# ipro7 register map
Vendor: intelpro; Series: BTBLE
CPU: ipro7, little endian
Registers are 32-bit, read-write, reset 0x0 unless marked. A register's access mark holds for its fields unless they carry their own. Offsets are from the block's base; [hi:lo] are bit positions.

## AON
Base 0x3008F000
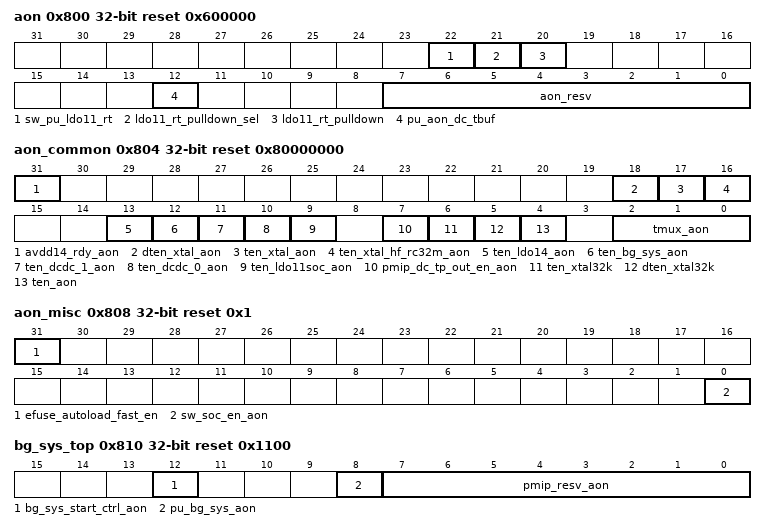
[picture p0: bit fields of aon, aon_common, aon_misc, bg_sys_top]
0x800 aon reset 0x600000
  [22] sw_pu_ldo11_rt
  [21] ldo11_rt_pulldown_sel — 0: hardware control pulldown when pu_ldo11rt=0, 1: register control
  [20] ldo11_rt_pulldown — 1: pulldown
  [12] pu_aon_dc_tbuf
  [7:0] aon_resv
0x804 aon_common reset 0x80000000 (reset mask 0x7FFFFFFF)
  [31] avdd14_rdy_aon ro — avdd14 power ready
  [18] dten_xtal_aon
  [17] ten_xtal_aon
  [16] ten_xtal_hf_rc32m_aon
  [13] ten_ldo14_aon — ldo14 dc test en
  [12] ten_bg_sys_aon — bgsys dc test en
  [11] ten_dcdc_1_aon — dcdc14 dc test1 en
  [10] ten_dcdc_0_aon — dcdc14 dc test0 en
  [9] ten_ldo11soc_aon
  [7] pmip_dc_tp_out_en_aon — dc test switch enable
  [6] ten_xtal32k — 32K crystal voltage test enable
  [5] dten_xtal32k — 32K crystal output clock test enable
  [4] ten_aon
  [2:0] tmux_aon
0x808 aon_misc reset 0x1
  [31] efuse_autoload_fast_en — 0:efuse autoload all 1k bits (49us) 1:efuse autoload first hw config words 0x0~0x8 only (9us) and release reset early
  [0] sw_soc_en_aon
0x810 bg_sys_top reset 0x1100
  [12] bg_sys_start_ctrl_aon — 0: supply voltage<2.3V, 1:supply voltage>=2.3V
  [8] pu_bg_sys_aon — power up system bandgap
  [7:0] pmip_resv_aon
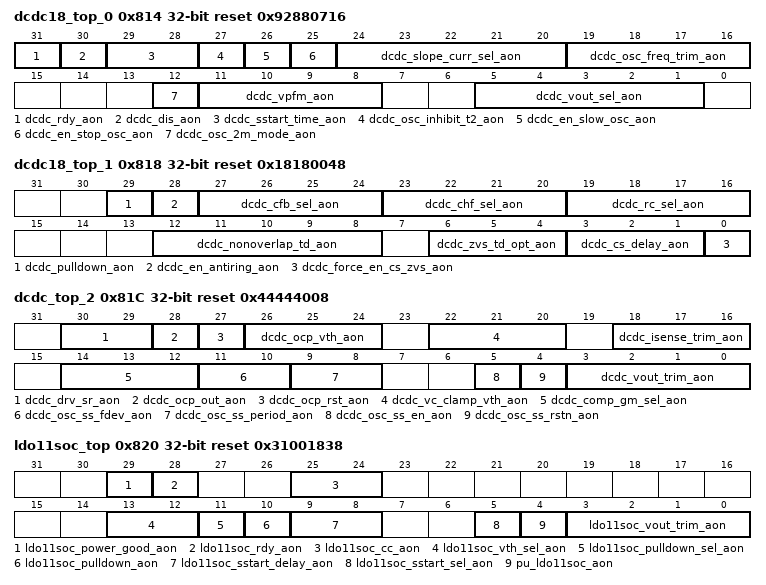
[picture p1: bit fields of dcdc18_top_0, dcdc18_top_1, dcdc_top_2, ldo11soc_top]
0x814 dcdc18_top_0 reset 0x92880716 (reset mask 0x7FFFFFFF)
  [31] dcdc_rdy_aon ro
  [30] dcdc_dis_aon — 1: disable dcdc function, for DCDC bypass mode
  [29:28] dcdc_sstart_time_aon — soft start time option
  [27] dcdc_osc_inhibit_t2_aon — inhibit t2 of osc
  [26] dcdc_en_slow_osc_aon — slow osc
  [25] dcdc_en_stop_osc_aon — stop osc
  [24:20] dcdc_slope_curr_sel_aon — current selection for slope compensation 8: if inductor value=2.2uH 14: if inductor value=1uH 4: if inductor value=4.7uH
  [19:16] dcdc_osc_freq_trim_aon — osc frequency trimming bits
  [12] dcdc_osc_2m_mode_aon — osc frequency selection, default 1MHz
  [11:8] dcdc_vpfm_aon — pfm mode threshold
  [5:1] dcdc_vout_sel_aon — output voltage selection, default 1.4V
0x818 dcdc18_top_1 reset 0x18180048
  [29] dcdc_pulldown_aon — output pulldown option 0: floating output when disable 1: pulldown output to ground when disable
  [28] dcdc_en_antiring_aon — antiring enable
  [27:24] dcdc_cfb_sel_aon — compensation cfb selection
  [23:20] dcdc_chf_sel_aon — compensation chf selection
  [19:16] dcdc_rc_sel_aon — compensation rc selection
  [12:8] dcdc_nonoverlap_td_aon — nonoverlap clock delay option
  [6:4] dcdc_zvs_td_opt_aon — zvs circuits enable delay option
  [3:1] dcdc_cs_delay_aon — cs circuits enable delay option
  [0] dcdc_force_en_cs_zvs_aon — force cs and zvs circuits enablable
0x81C dcdc_top_2 reset 0x44444008 (reset mask 0xEFFFFFFF)
  [30:29] dcdc_drv_sr_aon — powerMOS driver slew rate selection: 0: SR *1, 1: SR *2, 2: SR *4, 3: SR *40
  [28] dcdc_ocp_out_aon ro — ocp latched output
  [27] dcdc_ocp_rst_aon — reset dcdc_ocp_out_aon latch
  [26:24] dcdc_ocp_vth_aon — ocp threshold voltage
  [22:20] dcdc_vc_clamp_vth_aon — vc clamp threshold voltage
  [18:16] dcdc_isense_trim_aon — current sense R tuning
  [14:12] dcdc_comp_gm_sel_aon — compensator OTA gm tuning
  [11:10] dcdc_osc_ss_fdev_aon — osc spread spectrum frequency deviation
  [9:8] dcdc_osc_ss_period_aon — osc spread spectrum period
  [5] dcdc_osc_ss_en_aon — osc spread spectrum enable
  [4] dcdc_osc_ss_rstn_aon
  [3:0] dcdc_vout_trim_aon — output voltage trim 0: 93%, 1: 94%, 7: 100%, 8: 101%, 15: 108%
0x820 ldo11soc_top reset 0x31001838 (reset mask 0xCFFFFFFF)
  [29] ldo11soc_power_good_aon ro
  [28] ldo11soc_rdy_aon ro
  [25:24] ldo11soc_cc_aon — ldo11soc compensation capacitor option
  [13:12] ldo11soc_vth_sel_aon — vdd11soc pwr_ok detection threshold selection
  [11] ldo11soc_pulldown_sel_aon — ldo11 output pulldown signal selection 0: vout pulldown controlled by pd signal 1: vout pulldown controlled by pulldown signal
  [10] ldo11soc_pulldown_aon — vout pulldown signal 0: floating output 1: pulldown output to ground
  [9:8] ldo11soc_sstart_delay_aon — soft start delay time option
  [5] ldo11soc_sstart_sel_aon — ldo11 soft start select option 0: no soft start 1: with soft start function
  [4] pu_ldo11soc_aon — power up ldo11soc
  [3:0] ldo11soc_vout_trim_aon — output voltage trim: 0: 92%, .. 8: 100%, .. 15: 107%; 1%/step
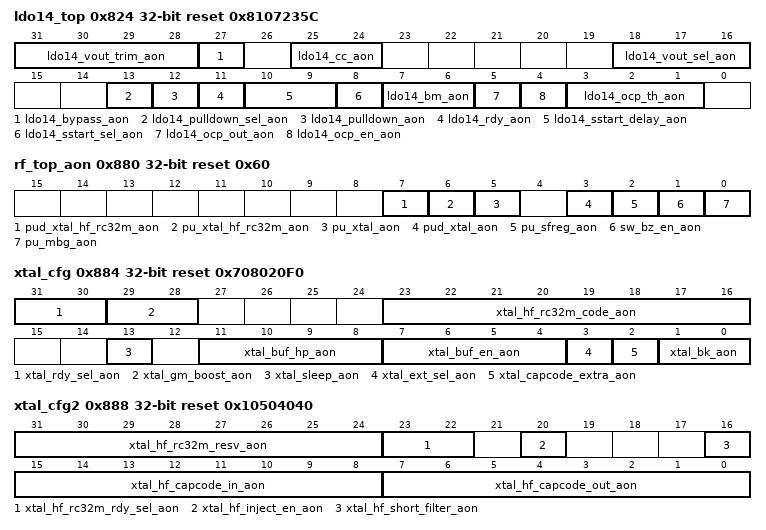
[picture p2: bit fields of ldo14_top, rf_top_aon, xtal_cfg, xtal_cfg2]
0x824 ldo14_top reset 0x8107235C (reset mask 0xFFFFF7DF)
  [31:28] ldo14_vout_trim_aon — output voltage trim 0: 92%, .. 8: 100%, .. 15: 107%; 1%/step
  [27] ldo14_bypass_aon — bypass enable. 702L_topldo14 donot have this function
  [25:24] ldo14_cc_aon — compensation capacitor option
  [18:16] ldo14_vout_sel_aon — output voltage selection, 0: 1.30, 1: 1.35, 2: 1.40, 3: 1.45, 4: 1.50, 5: 1.60, 6:1.70, 7: 1.80
  [13] ldo14_pulldown_sel_aon — output pulldown signal selection 0: vout pulldown controlled by pd signal 1: vout pulldown controlled by pulldown signal
  [12] ldo14_pulldown_aon — vout pulldown signal 0: floating output 1: pulldown output to ground
  [11] ldo14_rdy_aon ro — ldo14 ready signal
  [10:9] ldo14_sstart_delay_aon — soft-start delay time selection, 0: 50us, 1: 100us, 2: 150us, 3: 200us
  [8] ldo14_sstart_sel_aon — ldo14 soft start select option 0: no soft start 1: with soft start function
  [7:6] ldo14_bm_aon — bias mode selection
  [5] ldo14_ocp_out_aon ro — ldo14 ocp flag
  [4] ldo14_ocp_en_aon — ldo14 ocp enable
  [3:1] ldo14_ocp_th_aon — ocp threshold current selection; 0: 100mA, 1: 100mA, 2: 120mA, 3: 150mA, 4: 200mA, 5: 250mA, 6: 300mA, 7: 350mA
0x828 psw_irrcv
  [0] pu_ir_psw_aon — power up ir rx switch
0x82C rc32m_ctrl0_aon reset 0x60
  [7:0] rc32m_code_fr_ext — External code In for frequency setting
0x880 rf_top_aon reset 0x60 (reset mask 0xFFFFFF77)
  [7] pud_xtal_hf_rc32m_aon ro
  [6] pu_xtal_hf_rc32m_aon
  [5] pu_xtal_aon — power up xtal
  [3] pud_xtal_aon ro
  [2] pu_sfreg_aon
  [1] sw_bz_en_aon
  [0] pu_mbg_aon
0x884 xtal_cfg reset 0x708020F0
  [31:30] xtal_rdy_sel_aon — 0:128us, 1:256us, 2:512us, 3:1ms
  [29:28] xtal_gm_boost_aon — 1: larger negative gm in xtal
  [23:16] xtal_hf_rc32m_code_aon
  [13] xtal_sleep_aon — set 32M xtal in sleep mode
  [11:8] xtal_buf_hp_aon — set xtal buffer to high performance mode
  [7:4] xtal_buf_en_aon — enable xtal output buffer
  [3] xtal_ext_sel_aon — use offchip clock
  [2] xtal_capcode_extra_aon — Extra capacitor for supporting 15pF loading (also copy from efuse)
  [1:0] xtal_bk_aon — reseved for xtal
0x888 xtal_cfg2 reset 0x10504040
  [31:24] xtal_hf_rc32m_resv_aon — [3]: dten_xtal_rc32m_aon； [2]: dten_xtal_rc32m_rdy_aon； [5:4]: xtal_hf_ldo11_vsel；default 01 [6]: xtal_hf_injection_signal_sel; default 0
  [23:22] xtal_hf_rc32m_rdy_sel_aon
  [20] xtal_hf_inject_en_aon
  [16] xtal_hf_short_filter_aon
  [15:8] xtal_hf_capcode_in_aon — capcode for xtal at xtal_in node (also copy from efuse)
  [7:0] xtal_hf_capcode_out_aon — capcode for xtal at xtal_out node (also copy from efuse)
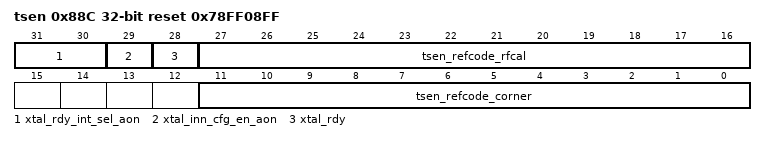
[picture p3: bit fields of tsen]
0x88C tsen reset 0x78FF08FF (reset mask 0xEFFFFFFF)
  [31:30] xtal_rdy_int_sel_aon — 0:4096*Txtal ~~~ 3:32768*Txtal, fast startup config time window
  [29] xtal_inn_cfg_en_aon — enable internal configuration for fast startup
  [28] xtal_rdy ro — xtal ready signal for soc clock used (rf performance not be gaurantee at this time shot)
  [27:16] tsen_refcode_rfcal — record temperature sensor reference code at RF_calibration
  [11:0] tsen_refcode_corner — record temperature sensor reference code at ATE for self corner calibration (also copy from efuse)
0x93C hbncore_resv0
  [31:0] hbncore_resv0_data
0x940 hbncore_resv1 reset 0xFFFFFFFF
  [31:0] hbncore_resv1_data
